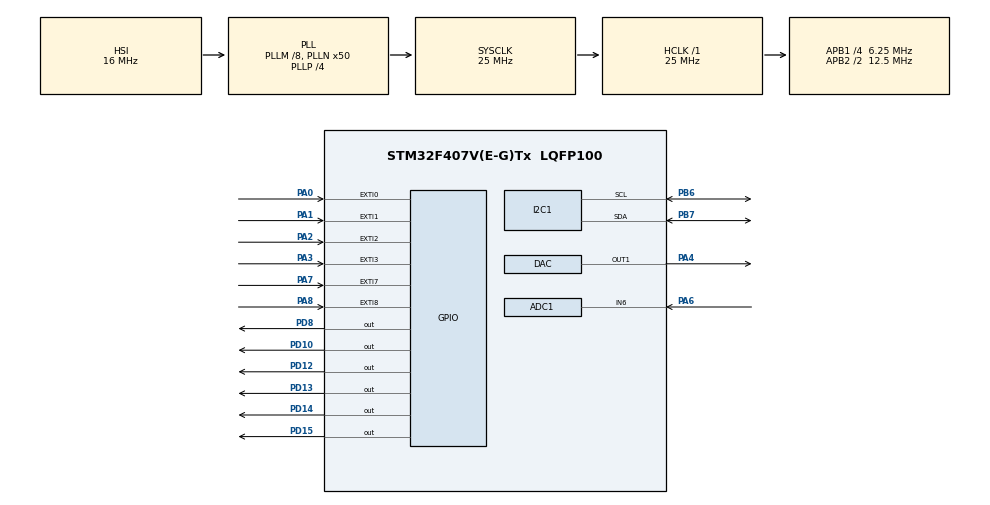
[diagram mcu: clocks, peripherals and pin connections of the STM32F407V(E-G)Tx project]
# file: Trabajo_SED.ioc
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ADC1.Channel-1\#ChannelRegularConversion=ADC_CHANNEL_6
ADC1.NbrOfConversionFlag=1
ADC1.Rank-1\#ChannelRegularConversion=1
ADC1.SamplingTime-1\#ChannelRegularConversion=ADC_SAMPLETIME_3CYCLES
ADC1.master=1
DAC.DAC_Trigger=DAC_TRIGGER_T2_TRGO
Dma.DAC1.0.Direction=DMA_MEMORY_TO_PERIPH
Dma.DAC1.0.FIFOMode=DMA_FIFOMODE_DISABLE
Dma.DAC1.0.Instance=DMA1_Stream5
Dma.DAC1.0.MemDataAlignment=DMA_MDATAALIGN_HALFWORD
Dma.DAC1.0.MemInc=DMA_MINC_ENABLE
Dma.DAC1.0.Mode=DMA_CIRCULAR
Dma.DAC1.0.PeriphDataAlignment=DMA_PDATAALIGN_HALFWORD
Dma.DAC1.0.PeriphInc=DMA_PINC_DISABLE
Dma.DAC1.0.Priority=DMA_PRIORITY_LOW
Dma.Request0=DAC1
Mcu.Family=STM32F4
Mcu.Name=STM32F407V(E-G)Tx
Mcu.Package=LQFP100
NVIC.DMA1_Stream5_IRQn=true\:0\:0\:false\:false\:true\:false\:true\:true
NVIC.EXTI0_IRQn=true\:0\:0\:false\:false\:true\:true\:true\:true
NVIC.EXTI1_IRQn=true\:0\:0\:false\:false\:true\:true\:true\:true
NVIC.EXTI2_IRQn=true\:0\:0\:false\:false\:true\:true\:true\:true
NVIC.EXTI3_IRQn=true\:0\:0\:false\:false\:true\:true\:true\:true
NVIC.EXTI9_5_IRQn=true\:0\:0\:false\:false\:true\:true\:true\:true
NVIC.PriorityGroup=NVIC_PRIORITYGROUP_0
NVIC.TIM3_IRQn=true\:0\:0\:false\:false\:true\:true\:true\:true
PA0-WKUP.GPIO_PuPd=GPIO_PULLDOWN
PA0-WKUP.Signal=GPXTI0
PA1.GPIO_PuPd=GPIO_PULLDOWN
PA1.Signal=GPXTI1
PA2.GPIO_PuPd=GPIO_PULLDOWN
PA2.Signal=GPXTI2
PA3.GPIO_PuPd=GPIO_PULLDOWN
PA3.Signal=GPXTI3
PA4.Signal=COMP_DAC1_group
PA6.Signal=ADCx_IN6
PA7.GPIO_PuPd=GPIO_PULLDOWN
PA7.Signal=GPXTI7
PA8.GPIO_PuPd=GPIO_PULLDOWN
PA8.Signal=GPXTI8
PB6.Mode=I2C
PB6.Signal=I2C1_SCL
PB7.Mode=I2C
PB7.Signal=I2C1_SDA
PD10.Signal=GPIO_Output
PD12.Signal=GPIO_Output
PD13.Signal=GPIO_Output
PD14.Signal=GPIO_Output
PD15.Signal=GPIO_Output
PD8.GPIO_PuPd=GPIO_NOPULL
PD8.Signal=GPIO_Output
ProjectManager.HeapSize=0x200
ProjectManager.StackSize=0x400
ProjectManager.TargetToolchain=STM32CubeIDE
RCC.48MHZClocksFreq_Value=14285714.285714285
RCC.AHBFreq_Value=25000000
RCC.APB1CLKDivider=RCC_HCLK_DIV4
RCC.APB1Freq_Value=6250000
RCC.APB1TimFreq_Value=12500000
RCC.APB2CLKDivider=RCC_HCLK_DIV2
RCC.APB2Freq_Value=12500000
RCC.APB2TimFreq_Value=25000000
RCC.CortexFreq_Value=25000000
RCC.HCLKFreq_Value=25000000
RCC.HSE_VALUE=8000000
RCC.HSI_VALUE=16000000
RCC.LSE_VALUE=32768
RCC.PLLM=8
RCC.PLLN=50
RCC.PLLP=RCC_PLLP_DIV4
RCC.PLLQ=7
RCC.SYSCLKFreq_VALUE=25000000
RCC.SYSCLKSource=RCC_SYSCLKSOURCE_PLLCLK
RCC.VCOOutputFreq_Value=100000000
SH.ADCx_IN6.0=ADC1_IN6,IN6
SH.COMP_DAC1_group.0=DAC_OUT1,DAC_OUT1
TIM2.Period=500
TIM2.Prescaler=124
TIM2.TIM_MasterOutputTrigger=TIM_TRGO_UPDATE
TIM3.Prescaler=1249
TIM4.Prescaler=1249
VP_TIM2_VS_ClockSourceINT.Mode=Internal
VP_TIM3_VS_ClockSourceINT.Mode=Internal
VP_TIM4_VS_ClockSourceINT.Mode=Internal
board=STM32F407G-DISC1

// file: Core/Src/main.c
/* USER CODE BEGIN Header */
/**
  ******************************************************************************
  * @file           : main.c
  * @brief          : Main program body
  ******************************************************************************
  * @attention
  *
  * Copyright (c) 2025 STMicroelectronics.
  * All rights reserved.
  *
  * This software is licensed under terms that can be found in the LICENSE file
  * in the root directory of this software component.
  * If no LICENSE file comes with this software, it is provided AS-IS.
  *
  ******************************************************************************
  */
/* USER CODE END Header */
#include "main.h"

/* USER CODE BEGIN Includes */
#include "juego.h"
/* USER CODE END Includes */

ADC_HandleTypeDef hadc1;

DAC_HandleTypeDef hdac;
DMA_HandleTypeDef hdma_dac1;

I2C_HandleTypeDef hi2c1;

TIM_HandleTypeDef htim2;
TIM_HandleTypeDef htim3;
TIM_HandleTypeDef htim4;

/* USER CODE BEGIN PV */
//static uint32_t tiempo_actual=0;
/* USER CODE END PV */

void SystemClock_Config(void);
static void MX_GPIO_Init(void);
static void MX_DMA_Init(void);
static void MX_ADC1_Init(void);
static void MX_DAC_Init(void);
static void MX_TIM3_Init(void);
static void MX_TIM4_Init(void);
static void MX_I2C1_Init(void);
static void MX_TIM2_Init(void);

int main(void)
{

  /* MCU Configuration--------------------------------------------------------*/

  /* Reset of all peripherals, Initializes the Flash interface and the Systick. */
  HAL_Init();

  /* Configure the system clock */
  SystemClock_Config();

  /* Initialize all configured peripherals */
  MX_GPIO_Init();
  MX_DMA_Init();
  MX_ADC1_Init();
  MX_DAC_Init();
  MX_TIM3_Init();
  MX_TIM4_Init();
  MX_I2C1_Init();
  MX_TIM2_Init();
  /* USER CODE BEGIN 2 */
  HAL_Delay(500);

  lcd_init();

  lcd_clear();
  lcd_enviar("PRESIONA START", 0, 0); // Opcional: Mensaje de bienvenida

  /* USER CODE END 2 */

  /* Infinite loop */
  /* USER CODE BEGIN WHILE */
  while (1)
  {

	  Juego();

    /* USER CODE END WHILE */

  }
}

void SystemClock_Config(void)
{
  RCC_OscInitTypeDef RCC_OscInitStruct = {0};
  RCC_ClkInitTypeDef RCC_ClkInitStruct = {0};

  /** Configure the main internal regulator output voltage
  */
  __HAL_RCC_PWR_CLK_ENABLE();
  __HAL_PWR_VOLTAGESCALING_CONFIG(PWR_REGULATOR_VOLTAGE_SCALE1);

  /** Initializes the RCC Oscillators according to the specified parameters
  * in the RCC_OscInitTypeDef structure.
  */
  RCC_OscInitStruct.OscillatorType = RCC_OSCILLATORTYPE_HSI;
  RCC_OscInitStruct.HSIState = RCC_HSI_ON;
  RCC_OscInitStruct.HSICalibrationValue = RCC_HSICALIBRATION_DEFAULT;
  RCC_OscInitStruct.PLL.PLLState = RCC_PLL_ON;
  RCC_OscInitStruct.PLL.PLLSource = RCC_PLLSOURCE_HSI;
  RCC_OscInitStruct.PLL.PLLM = 8;
  RCC_OscInitStruct.PLL.PLLN = 50;
  RCC_OscInitStruct.PLL.PLLP = RCC_PLLP_DIV4;
  RCC_OscInitStruct.PLL.PLLQ = 7;
  if (HAL_RCC_OscConfig(&RCC_OscInitStruct) != HAL_OK)
  {
    Error_Handler();
  }

  /** Initializes the CPU, AHB and APB buses clocks
  */
  RCC_ClkInitStruct.ClockType = RCC_CLOCKTYPE_HCLK|RCC_CLOCKTYPE_SYSCLK
                              |RCC_CLOCKTYPE_PCLK1|RCC_CLOCKTYPE_PCLK2;
  RCC_ClkInitStruct.SYSCLKSource = RCC_SYSCLKSOURCE_PLLCLK;
  RCC_ClkInitStruct.AHBCLKDivider = RCC_SYSCLK_DIV1;
  RCC_ClkInitStruct.APB1CLKDivider = RCC_HCLK_DIV4;
  RCC_ClkInitStruct.APB2CLKDivider = RCC_HCLK_DIV2;

  if (HAL_RCC_ClockConfig(&RCC_ClkInitStruct, FLASH_LATENCY_0) != HAL_OK)
  {
    Error_Handler();
  }
}

static void MX_ADC1_Init(void)
{

  ADC_ChannelConfTypeDef sConfig = {0};

  /** Configure the global features of the ADC (Clock, Resolution, Data Alignment and number of conversion)
  */
  hadc1.Instance = ADC1;
  hadc1.Init.ClockPrescaler = ADC_CLOCK_SYNC_PCLK_DIV2;
  hadc1.Init.Resolution = ADC_RESOLUTION_12B;
  hadc1.Init.ScanConvMode = DISABLE;
  hadc1.Init.ContinuousConvMode = DISABLE;
  hadc1.Init.DiscontinuousConvMode = DISABLE;
  hadc1.Init.ExternalTrigConvEdge = ADC_EXTERNALTRIGCONVEDGE_NONE;
  hadc1.Init.ExternalTrigConv = ADC_SOFTWARE_START;
  hadc1.Init.DataAlign = ADC_DATAALIGN_RIGHT;
  hadc1.Init.NbrOfConversion = 1;
  hadc1.Init.DMAContinuousRequests = DISABLE;
  hadc1.Init.EOCSelection = ADC_EOC_SINGLE_CONV;
  if (HAL_ADC_Init(&hadc1) != HAL_OK)
  {
    Error_Handler();
  }

  /** Configure for the selected ADC regular channel its corresponding rank in the sequencer and its sample time.
  */
  sConfig.Channel = ADC_CHANNEL_6;
  sConfig.Rank = 1;
  sConfig.SamplingTime = ADC_SAMPLETIME_3CYCLES;
  if (HAL_ADC_ConfigChannel(&hadc1, &sConfig) != HAL_OK)
  {
    Error_Handler();
  }

}

static void MX_DAC_Init(void)
{

  DAC_ChannelConfTypeDef sConfig = {0};

  /** DAC Initialization
  */
  hdac.Instance = DAC;
  if (HAL_DAC_Init(&hdac) != HAL_OK)
  {
    Error_Handler();
  }

  /** DAC channel OUT1 config
  */
  sConfig.DAC_Trigger = DAC_TRIGGER_T2_TRGO;
  sConfig.DAC_OutputBuffer = DAC_OUTPUTBUFFER_ENABLE;
  if (HAL_DAC_ConfigChannel(&hdac, &sConfig, DAC_CHANNEL_1) != HAL_OK)
  {
    Error_Handler();
  }

}

static void MX_I2C1_Init(void)
{

  hi2c1.Instance = I2C1;
  hi2c1.Init.ClockSpeed = 100000;
  hi2c1.Init.DutyCycle = I2C_DUTYCYCLE_2;
  hi2c1.Init.OwnAddress1 = 0;
  hi2c1.Init.AddressingMode = I2C_ADDRESSINGMODE_7BIT;
  hi2c1.Init.DualAddressMode = I2C_DUALADDRESS_DISABLE;
  hi2c1.Init.OwnAddress2 = 0;
  hi2c1.Init.GeneralCallMode = I2C_GENERALCALL_DISABLE;
  hi2c1.Init.NoStretchMode = I2C_NOSTRETCH_DISABLE;
  if (HAL_I2C_Init(&hi2c1) != HAL_OK)
  {
    Error_Handler();
  }

}

static void MX_TIM2_Init(void)
{

  TIM_ClockConfigTypeDef sClockSourceConfig = {0};
  TIM_MasterConfigTypeDef sMasterConfig = {0};

  htim2.Instance = TIM2;
  htim2.Init.Prescaler = 124;
  htim2.Init.CounterMode = TIM_COUNTERMODE_UP;
  htim2.Init.Period = 500;
  htim2.Init.ClockDivision = TIM_CLOCKDIVISION_DIV1;
  htim2.Init.AutoReloadPreload = TIM_AUTORELOAD_PRELOAD_DISABLE;
  if (HAL_TIM_Base_Init(&htim2) != HAL_OK)
  {
    Error_Handler();
  }
  sClockSourceConfig.ClockSource = TIM_CLOCKSOURCE_INTERNAL;
  if (HAL_TIM_ConfigClockSource(&htim2, &sClockSourceConfig) != HAL_OK)
  {
    Error_Handler();
  }
  sMasterConfig.MasterOutputTrigger = TIM_TRGO_UPDATE;
  sMasterConfig.MasterSlaveMode = TIM_MASTERSLAVEMODE_DISABLE;
  if (HAL_TIMEx_MasterConfigSynchronization(&htim2, &sMasterConfig) != HAL_OK)
  {
    Error_Handler();
  }

}

static void MX_TIM3_Init(void)
{

  TIM_ClockConfigTypeDef sClockSourceConfig = {0};
  TIM_MasterConfigTypeDef sMasterConfig = {0};

  htim3.Instance = TIM3;
  htim3.Init.Prescaler = 1249;
  htim3.Init.CounterMode = TIM_COUNTERMODE_UP;
  htim3.Init.Period = 65535;
  htim3.Init.ClockDivision = TIM_CLOCKDIVISION_DIV1;
  htim3.Init.AutoReloadPreload = TIM_AUTORELOAD_PRELOAD_DISABLE;
  if (HAL_TIM_Base_Init(&htim3) != HAL_OK)
  {
    Error_Handler();
  }
  sClockSourceConfig.ClockSource = TIM_CLOCKSOURCE_INTERNAL;
  if (HAL_TIM_ConfigClockSource(&htim3, &sClockSourceConfig) != HAL_OK)
  {
    Error_Handler();
  }
  sMasterConfig.MasterOutputTrigger = TIM_TRGO_RESET;
  sMasterConfig.MasterSlaveMode = TIM_MASTERSLAVEMODE_DISABLE;
  if (HAL_TIMEx_MasterConfigSynchronization(&htim3, &sMasterConfig) != HAL_OK)
  {
    Error_Handler();
  }

}

static void MX_TIM4_Init(void)
{

  TIM_ClockConfigTypeDef sClockSourceConfig = {0};
  TIM_MasterConfigTypeDef sMasterConfig = {0};

  htim4.Instance = TIM4;
  htim4.Init.Prescaler = 1249;
  htim4.Init.CounterMode = TIM_COUNTERMODE_UP;
  htim4.Init.Period = 65535;
  htim4.Init.ClockDivision = TIM_CLOCKDIVISION_DIV1;
  htim4.Init.AutoReloadPreload = TIM_AUTORELOAD_PRELOAD_DISABLE;
  if (HAL_TIM_Base_Init(&htim4) != HAL_OK)
  {
    Error_Handler();
  }
  sClockSourceConfig.ClockSource = TIM_CLOCKSOURCE_INTERNAL;
  if (HAL_TIM_ConfigClockSource(&htim4, &sClockSourceConfig) != HAL_OK)
  {
    Error_Handler();
  }
  sMasterConfig.MasterOutputTrigger = TIM_TRGO_RESET;
  sMasterConfig.MasterSlaveMode = TIM_MASTERSLAVEMODE_DISABLE;
  if (HAL_TIMEx_MasterConfigSynchronization(&htim4, &sMasterConfig) != HAL_OK)
  {
    Error_Handler();
  }

}

static void MX_DMA_Init(void)
{

  /* DMA controller clock enable */
  __HAL_RCC_DMA1_CLK_ENABLE();

  /* DMA interrupt init */
  /* DMA1_Stream5_IRQn interrupt configuration */
  HAL_NVIC_SetPriority(DMA1_Stream5_IRQn, 0, 0);
  HAL_NVIC_EnableIRQ(DMA1_Stream5_IRQn);

}

static void MX_GPIO_Init(void)
{
  GPIO_InitTypeDef GPIO_InitStruct = {0};

  /* GPIO Ports Clock Enable */
  __HAL_RCC_GPIOA_CLK_ENABLE();
  __HAL_RCC_GPIOD_CLK_ENABLE();
  __HAL_RCC_GPIOB_CLK_ENABLE();

  /*Configure GPIO pin Output Level */
  HAL_GPIO_WritePin(GPIOD, GPIO_PIN_8|GPIO_PIN_10|GPIO_PIN_12|GPIO_PIN_13
                          |GPIO_PIN_14|GPIO_PIN_15, GPIO_PIN_RESET);

  /*Configure GPIO pins : PA0 PA1 PA2 PA3
                           PA7 PA8 */
  GPIO_InitStruct.Pin = GPIO_PIN_0|GPIO_PIN_1|GPIO_PIN_2|GPIO_PIN_3
                          |GPIO_PIN_7|GPIO_PIN_8;
  GPIO_InitStruct.Mode = GPIO_MODE_IT_RISING;
  GPIO_InitStruct.Pull = GPIO_PULLDOWN;
  HAL_GPIO_Init(GPIOA, &GPIO_InitStruct);

  /*Configure GPIO pins : PD8 PD10 PD12 PD13
                           PD14 PD15 */
  GPIO_InitStruct.Pin = GPIO_PIN_8|GPIO_PIN_10|GPIO_PIN_12|GPIO_PIN_13
                          |GPIO_PIN_14|GPIO_PIN_15;
  GPIO_InitStruct.Mode = GPIO_MODE_OUTPUT_PP;
  GPIO_InitStruct.Pull = GPIO_NOPULL;
  GPIO_InitStruct.Speed = GPIO_SPEED_FREQ_LOW;
  HAL_GPIO_Init(GPIOD, &GPIO_InitStruct);

  /* EXTI interrupt init*/
  HAL_NVIC_SetPriority(EXTI0_IRQn, 0, 0);
  HAL_NVIC_EnableIRQ(EXTI0_IRQn);

  HAL_NVIC_SetPriority(EXTI1_IRQn, 0, 0);
  HAL_NVIC_EnableIRQ(EXTI1_IRQn);

  HAL_NVIC_SetPriority(EXTI2_IRQn, 0, 0);
  HAL_NVIC_EnableIRQ(EXTI2_IRQn);

  HAL_NVIC_SetPriority(EXTI3_IRQn, 0, 0);
  HAL_NVIC_EnableIRQ(EXTI3_IRQn);

  HAL_NVIC_SetPriority(EXTI9_5_IRQn, 0, 0);
  HAL_NVIC_EnableIRQ(EXTI9_5_IRQn);

}

void Error_Handler(void)
{
  __disable_irq();
  while (1)
  {
  }
}
